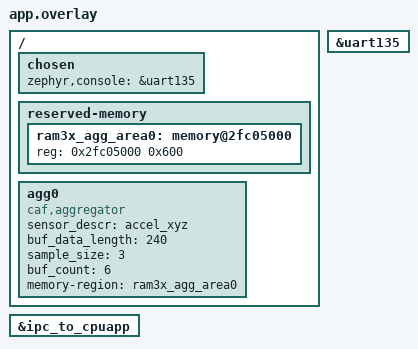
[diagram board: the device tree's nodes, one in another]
/*
 * Copyright (c) 2023 Nordic Semiconductor ASA
 *
 * SPDX-License-Identifier: LicenseRef-Nordic-5-Clause
 */

 / {
	chosen {
		zephyr,console = &uart135;
	};

	reserved-memory {
		ram3x_agg_area0: memory@2fc05000 {
			reg = <0x2fc05000 0x600>;
		};
	};

	agg0: agg0 {
		compatible = "caf,aggregator";
		sensor_descr = "accel_xyz";
		buf_data_length = <240>;
		sample_size = <3>;
		buf_count = <6>;
		memory-region = <&ram3x_agg_area0>;
		status = "okay";
	};
};

&uart135 {
	status = "okay";
};

ipc0: &ipc_to_cpuapp {
	status = "okay";
};
